# R7FA0E107 register map
Vendor: Renesas Electronics Corporation; Series: RA0; File version: 1.10.00
CPU: CM23 r1p0, little endian, no MPU, no FPU, VTOR, 2 interrupt priority bits, 64 interrupts
Registers are 16-bit, read-write, reset 0x0 unless marked. A register's access mark holds for its fields unless they carry their own. Offsets are from the block's base; [hi:lo] are bit positions; {n}, {i} and the like mark numbered series.

## PORGA — Product Organize
Base 0x400A1000
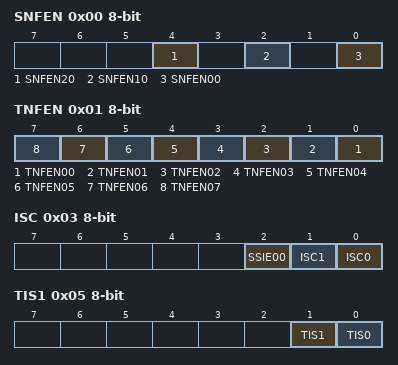
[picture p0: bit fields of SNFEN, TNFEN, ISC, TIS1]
0x00 SNFEN 8-bit — SAU Noise Filter Enable Register
  [all] fields
    0=Noise filter OFF; 1=Noise filter ON
  [4] SNFEN20 — Use of Noise Filter of RXD2 Pin
  [2] SNFEN10 — Use of Noise Filter of RXD1 Pin
  [0] SNFEN00 — Use of Noise Filter of RXD0 Pin
0x01 TNFEN 8-bit — TAU Noise Filter Enable Register
  [all] fields
    0=Turns the noise filter off; 1=Turns the noise filter on
  [n] TNFEN{n:02} (n=0..7) — Enabling or Disabling Use of the Noise Filter for the TI{n:02} Pin
0x03 ISC 8-bit — Input Switch Control Register
  [2] SSIE00 — Setting of the SSI00 Input of Channel 0 in the Communications Through SPI00 in the Slave Mode
    0=The SSI00 input is disabled; 1=The SSI00 input is enabled
  [1] ISC1 — Switching Channel 7 Input of Timer Array Unit
    0=Uses the input signal of the TI07 pin as a timer input (normal operation); 1=Input signal of the RXD2 pin is used as timer input (detects the wakeup signal and measures the low width of the break field and the pulse width of the sync field)
  [0] ISC0 — Switching External Interrupt (IRQ0) Input
    0=Uses the input signal of the IRQ0 pin as an external interrupt (normal operation); 1=Uses the input signal of the RXD2 pin as an external interrupt (wakeup signal detection)
0x04 TIS0 8-bit — Timer Input Select Register 0
  [2:0] TIS — Selection of Timer Input Used with Channel 5
    0=Input signal of timer input pin (TI05); 3=Middle-speed on-chip oscillator (MOCO); 4=Low-speed on-chip oscillator (LOCO); 5=Sub System clock (FSUB); other=Others (Setting prohibited)
0x05 TIS1 8-bit — Timer Input Select Register 1
  [1] TIS1 — Selection of Timer Input Used with Channel 1
    0=Input signal of timer input pin (TI01); 1=Event input signal from ELC
  [0] TIS0 — Selection of Timer Input Used with Channel 0
    0=Input signal of timer input pin (TI00); 1=Event input signal from ELC
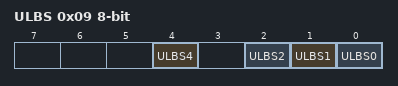
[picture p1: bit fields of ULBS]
0x09 ULBS 8-bit — UART Loopback Select Register
  [4] ULBS4 — Selection of the UARTA Loopback Function
    0=Inputs the states of the RXDA0 pin of serial interface UARTA0 to the reception shift register; 1=Loops back output from the transmission shift register to the reception shift register
  [2] ULBS2 — Selection of the UART2 Loopback Function
    0=Inputs the states of the RXD2 pin of serial array unit UART2 to the reception shift register; 1=Loops back output from the transmission shift register to the reception shift register
  [1] ULBS1 — Selection of the UART1 Loopback Function
    0=Inputs the states of the RXD1 pin of serial array unit UART1 to the reception shift register; 1=Loops back output from the transmission shift register to the reception shift register
  [0] ULBS0 — Selection of the UART0 Loopback Function
    0=Inputs the states of the RXD0 pin of serial array unit UART0 to the reception shift register; 1=Loops back output from the transmission shift register to the reception shift register

## UARTA — Serial Interface UARTA
Base 0x400A3400
0x00 TXBA0 8-bit reset 0xFF — Transmit Buffer Register 0
0x01 RXBA0 8-bit ro reset 0xFF — Receive Buffer Register 0
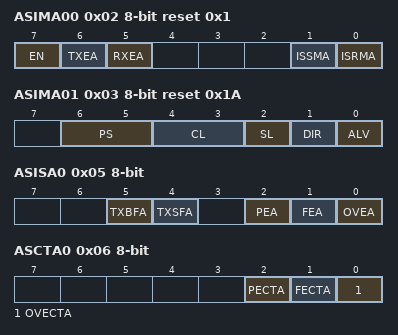
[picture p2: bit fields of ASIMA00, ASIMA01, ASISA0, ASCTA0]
0x02 ASIMA00 8-bit reset 0x1 — Operation Mode Setting Register 00
  [7] EN — UART Operation Enable
    0=Disables the UART operation clock (resets the internal circuits); 1=Enables the UART operation clock
  [6] TXEA — Transmission Enable
    0=Disables transmission (resets the transmission circuit); 1=Enables transmission
  [5] RXEA — Reception Enable
    0=Disables reception (reset the reception circuit); 1=Enables reception
  [1] ISSMA — Transmit Interrupt Mode Select
    0=The UARTA0_TXI interrupt is generated on completion of transmission; 1=The UARTA0_TXI interrupt is generated when the transmit buffer becomes empty (for continuous transmission)
  [0] ISRMA — Receive Interrupt Mode Select
    0=The UARTA0_ERRI interrupt is generated when a reception error occurs (UARTA0_RXI is not generated); 1=The UARTA0_RXI interrupt is generated when a reception error occurs (UARTA0_ERRI is not generated)
0x03 ASIMA01 8-bit reset 0x1A — Operation Mode Setting Register 01
  [6:5] PS — Transmission and Reception Parity Bit Setting
    0=Transmission: No parity bit is output. Reception: Data is received without parity.; 1=Transmission: 0 parity is output. Reception: Data is received with 0 parity.; 2=Transmission: Odd parity is output. Reception: Check is made for odd parity.; 3=Transmission: Even parity is output. Reception: Check is made for even parity.
  [4:3] CL — Transmission and Reception Character Length Setting
    0=Character length of data = 5 bits; 1=Setting prohibited; 2=Character length of data = 7 bits; 3=Character length of data = 8 bits
  [2] SL — Transmission Stop Bit Length Setting
    0=Stop bit length = 1 bit; 1=Stop bit length = 2 bits
  [1] DIR — Transmission and Reception Order Setting
    0=MSB first; 1=LSB first
  [0] ALV — Transmission and Reception Level Setting
    0=Positive logic (wait state = high level, start bit = low level, stop bit = high level); 1=Negative logic (wait state = low level, start bit = high level, stop bit = low level)
0x04 BRGCA0 8-bit reset 0xFF — Baud Rate Generator Control Register 0
0x05 ASISA0 8-bit ro — Status Register 0
  [5] TXBFA — Transmit Buffer Data Flag
    0=No valid data exists in the TXBA0 register; 1=Valid data exists in the TXBA0 register
  [4] TXSFA — Transmit Shift Register Data Flag
    0=Data is not being transmitted; 1=Data is being transmitted
  [2] PEA — Parity Error Flag
    0=No error has occurred; 1=An error has occurred
  [1] FEA — Framing Error Flag
    0=No error has occurred; 1=An error has occurred
  [0] OVEA — Overrun Error Flag
    0=No error has occurred; 1=An error has occurred
0x06 ASCTA0 8-bit — Status Clear Trigger Register 0
  [2] PECTA — Parity Error Flag Clear Trigger
    0=Does not clear the ASISA0.PEA flag (the flag is retained); 1=Clears the ASISA0.PEA flag
  [1] FECTA — Framing Error Flag Clear Trigger
    0=Does not clear the ASISA0.FEA flag (the flag is retained); 1=Clears the ASISA0.FEA flag
  [0] OVECTA — Overrun Error Flag Clear Trigger
    0=Does not clear the ASISA0.OVEA flag (the flag is retained); 1=Clears the ASISA0.OVEA flag
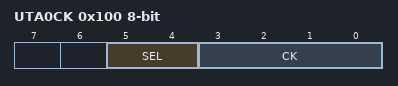
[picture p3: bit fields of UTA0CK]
0x100 UTA0CK 8-bit — UARTA Clock Select Register 0
  [5:4] SEL — fSEL Clock Select
    0=Stop; 1=MOSC; 2=HOCO; 3=MOCO
  [3:0] CK — UARTA0 Operation Clock Select (fUTA0)
    0=fSEL; 1=fSEL/2; 2=fSEL/4; 3=fSEL/8; 4=fSEL/16; 5=fSEL/32; 6=fSEL/64; 8=FSXP; other=Others (Setting prohibited)

## PCLBUZ — Clock Output/Buzzer Output Controller
Base 0x400A3B00
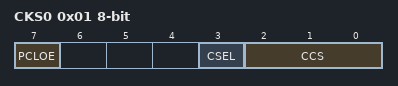
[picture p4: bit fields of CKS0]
0x01 CKS0 8-bit — Clock Out Control Register 0
  [7] PCLOE — Clock Out Enable
    0=Disable clock out; 1=Enable clock out
  [3] CSEL — Clock Out Select
    0=FMAIN; 1=FSUB
  [2:0] CCS — Clock Out Divide Select
    0=value after reset FMAIN (When CKS0.CSEL = 0) FSUB (When CKS0.CSEL = 1); 1=FMAIN × 1/2 (When CKS0.CSEL = 0) FSUB × 1/2 (When CKS0.CSEL = 1); 2=FMAIN × 1/22 (When CKS0.CSEL = 0) FSUB × 1/22 (When CKS0.CSEL = 1); 3=FMAIN × 1/23 (When CKS0.CSEL = 0) FSUB × 1/23 (When CKS0.CSEL = 1); 4=FMAIN × 1/24 (When CKS0.CSEL = 0) FSUB × 1/24 (When CKS0.CSEL = 1); 5=FMAIN × 1/211 (When CKS0.CSEL = 0) FSUB × 1/25 (When CKS0.CSEL = 1); 6=FMAIN 1/212 (When CKS0.CSEL = 0) FSUB × 1/26 (When CKS0.CSEL = 1); 7=FMAIN × 1/213 (When CKS0.CSEL = 0) FSUB × 1/27 (When CKS0.CSEL = 1)

## TRNG — True Random Number Generator
Base 0x400D1000
0x00 TRNGSDR 8-bit ro — TRNG Seed Data Register
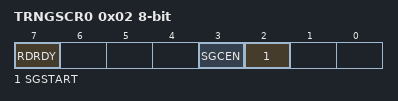
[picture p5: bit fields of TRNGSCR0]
0x02 TRNGSCR0 8-bit — TRNG Seed Command Register 0
  [7] RDRDY ro — Read Ready
  [3] SGCEN — Seed Generation Circuit Enable
    0=Seed generation circuit is disable; 1=Seed generation circuit is enable
  [2] SGSTART wo — Seed Generation Start
    0=No effect; 1=Start to generate the seed data
0x03 TRNGSCR1 8-bit — TRNG Seed Command Register 1
  [0] INTEN — TRNG Interrupt Enable
    0=TRNG interrupt is disabled; 1=TRNG interrupt is enabled
